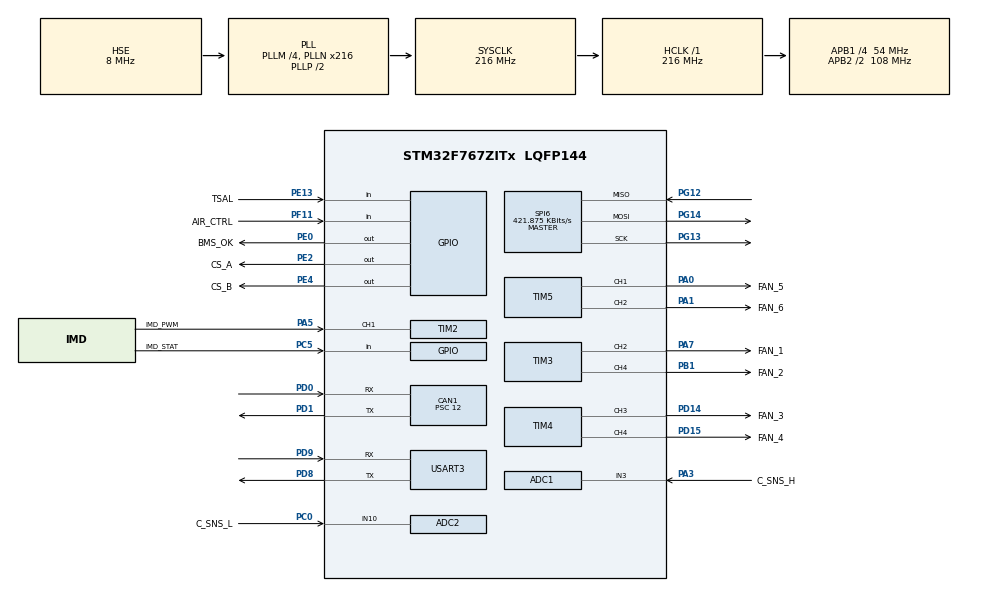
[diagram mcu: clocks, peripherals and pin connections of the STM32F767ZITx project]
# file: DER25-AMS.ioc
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ADC1.Channel-0\#ChannelRegularConversion=ADC_CHANNEL_3
ADC1.ClockPrescaler=ADC_CLOCK_SYNC_PCLK_DIV6
ADC1.NbrOfConversionFlag=1
ADC1.Rank-0\#ChannelRegularConversion=1
ADC1.SamplingTime-0\#ChannelRegularConversion=ADC_SAMPLETIME_3CYCLES
ADC1.master=1
ADC2.Channel-0\#ChannelRegularConversion=ADC_CHANNEL_10
ADC2.ClockPrescaler=ADC_CLOCK_SYNC_PCLK_DIV6
ADC2.NbrOfConversionFlag=1
ADC2.Rank-0\#ChannelRegularConversion=1
ADC2.SamplingTime-0\#ChannelRegularConversion=ADC_SAMPLETIME_3CYCLES
CAN1.ABOM=ENABLE
CAN1.AWUM=ENABLE
CAN1.BS1=CAN_BS1_15TQ
CAN1.BS2=CAN_BS2_2TQ
CAN1.CalculateBaudRate=250000
CAN1.CalculateTimeBit=4000
CAN1.CalculateTimeQuantum=222.22222222222223
CAN1.Prescaler=12
CORTEX_M7.MPU_Control=__NULL
CORTEX_M7.default_mode_Activation=1
FREERTOS.Tasks01=defaultTask,24,128,StartDefaultTask,Default,NULL,Dynamic,NULL,NULL
FREERTOS.configENABLE_FPU=1
FREERTOS.configUSE_NEWLIB_REENTRANT=1
Mcu.Family=STM32F7
Mcu.Name=STM32F767ZITx
Mcu.Package=LQFP144
NVIC.CAN1_RX0_IRQn=true\:5\:0\:false\:false\:true\:true\:true\:true\:true
NVIC.PriorityGroup=NVIC_PRIORITYGROUP_4
NVIC.TIM2_IRQn=true\:5\:0\:false\:false\:true\:true\:true\:true\:true
NVIC.TIM7_IRQn=true\:15\:0\:false\:false\:true\:false\:false\:true\:true
NVIC.TimeBase=TIM7_IRQn
NVIC.TimeBaseIP=TIM7
NVIC.USART3_IRQn=true\:5\:0\:false\:false\:true\:true\:true\:true\:true
PA0/WKUP.GPIO_Label=FAN_5
PA0/WKUP.Signal=S_TIM5_CH1
PA1.GPIO_Label=FAN_6
PA1.Signal=S_TIM5_CH2
PA13.Mode=Serial_Wire
PA13.Signal=SYS_JTMS-SWDIO
PA14.Mode=Serial_Wire
PA14.Signal=SYS_JTCK-SWCLK
PA3.GPIO_Label=C_SNS_H
PA3.Signal=ADCx_IN3
PA5.GPIO_Label=IMD_PWM
PA5.Signal=S_TIM2_CH1_ETR
PA7.GPIO_Label=FAN_1
PA7.Signal=S_TIM3_CH2
PB1.GPIO_Label=FAN_2
PB1.Signal=S_TIM3_CH4
PC0.GPIO_Label=C_SNS_L
PC0.Signal=ADCx_IN10
PC14/OSC32_IN.Mode=LSE-External-Oscillator
PC14/OSC32_IN.Signal=RCC_OSC32_IN
PC15/OSC32_OUT.Mode=LSE-External-Oscillator
PC15/OSC32_OUT.Signal=RCC_OSC32_OUT
PC5.GPIO_Label=IMD_STAT
PC5.Signal=GPIO_Input
PD0.Mode=CAN_Activate
PD0.Signal=CAN1_RX
PD1.Mode=CAN_Activate
PD1.Signal=CAN1_TX
PD14.GPIO_Label=FAN_3
PD14.Signal=S_TIM4_CH3
PD15.GPIO_Label=FAN_4
PD15.Signal=S_TIM4_CH4
PD8.Mode=Asynchronous
PD8.Signal=USART3_TX
PD9.Mode=Asynchronous
PD9.Signal=USART3_RX
PE0.GPIO_Label=BMS_OK
PE0.Signal=GPIO_Output
PE13.GPIO_Label=TSAL
PE13.Signal=GPIO_Input
PE2.GPIO_Label=CS_A
PE2.Signal=GPIO_Output
PE4.GPIO_Label=CS_B
PE4.Signal=GPIO_Output
PF11.GPIO_Label=AIR_CTRL
PF11.Signal=GPIO_Input
PG12.Mode=Full_Duplex_Master
PG12.Signal=SPI6_MISO
PG13.Mode=Full_Duplex_Master
PG13.Signal=SPI6_SCK
PG14.Mode=Full_Duplex_Master
PG14.Signal=SPI6_MOSI
PH0/OSC_IN.Mode=HSE-External-Oscillator
PH0/OSC_IN.Signal=RCC_OSC_IN
PH1/OSC_OUT.Mode=HSE-External-Oscillator
PH1/OSC_OUT.Signal=RCC_OSC_OUT
ProjectManager.HeapSize=0x200
ProjectManager.StackSize=0x400
ProjectManager.TargetToolchain=STM32CubeIDE
RCC.AHBFreq_Value=216000000
RCC.APB1CLKDivider=RCC_HCLK_DIV4
RCC.APB1Freq_Value=54000000
RCC.APB1TimFreq_Value=108000000
RCC.APB2CLKDivider=RCC_HCLK_DIV2
RCC.APB2Freq_Value=108000000
RCC.APB2TimFreq_Value=216000000
RCC.CortexFreq_Value=216000000
RCC.HCLKFreq_Value=216000000
RCC.HSE_VALUE=8000000
RCC.HSI_VALUE=16000000
RCC.PLLM=4
RCC.PLLN=216
RCC.PLLSourceVirtual=RCC_PLLSOURCE_HSE
RCC.SYSCLKFreq_VALUE=216000000
RCC.SYSCLKSource=RCC_SYSCLKSOURCE_PLLCLK
RCC.USBFreq_Value=216000000
RCC.VCOOutputFreq_Value=432000000
SH.ADCx_IN10.0=ADC2_IN10,IN10
SH.ADCx_IN3.0=ADC1_IN3,IN3
SH.S_TIM2_CH1_ETR.0=TIM2_CH1,PWM_Input_1
SH.S_TIM3_CH2.0=TIM3_CH2,PWM Generation2 CH2
SH.S_TIM3_CH4.0=TIM3_CH4,PWM Generation4 CH4
SH.S_TIM4_CH3.0=TIM4_CH3,PWM Generation3 CH3
SH.S_TIM4_CH4.0=TIM4_CH4,PWM Generation4 CH4
SH.S_TIM5_CH1.0=TIM5_CH1,PWM Generation1 CH1
SH.S_TIM5_CH2.0=TIM5_CH2,PWM Generation2 CH2
SPI6.BaudRatePrescaler=SPI_BAUDRATEPRESCALER_256
SPI6.CLKPhase=SPI_PHASE_2EDGE
SPI6.CLKPolarity=SPI_POLARITY_LOW
SPI6.CalculateBaudRate=421.875 KBits/s
SPI6.DataSize=SPI_DATASIZE_8BIT
SPI6.Direction=SPI_DIRECTION_2LINES
SPI6.Mode=SPI_MODE_MASTER
SPI6.VirtualType=VM_MASTER
TIM1.AutoReloadPreload=TIM_AUTORELOAD_PRELOAD_ENABLE
TIM1.Prescaler=215
TIM3.Channel-PWM\ Generation2\ CH2=TIM_CHANNEL_2
TIM3.Channel-PWM\ Generation4\ CH4=TIM_CHANNEL_4
TIM4.Channel-PWM\ Generation3\ CH3=TIM_CHANNEL_3
TIM4.Channel-PWM\ Generation4\ CH4=TIM_CHANNEL_4
TIM5.Channel-PWM\ Generation1\ CH1=TIM_CHANNEL_1
TIM5.Channel-PWM\ Generation2\ CH2=TIM_CHANNEL_2
USART3.VirtualMode-Asynchronous=VM_ASYNC
VP_FREERTOS_VS_CMSIS_V2.Mode=CMSIS_V2
VP_SYS_VS_tim7.Mode=TIM7
VP_TIM1_VS_ClockSourceINT.Mode=Internal
VP_TIM2_VS_ClockSourceINT.Mode=Internal
VP_TIM3_VS_ClockSourceINT.Mode=Internal
VP_TIM4_VS_ClockSourceINT.Mode=Internal
VP_TIM5_VS_ClockSourceINT.Mode=Internal
board=custom

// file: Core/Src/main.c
/* USER CODE BEGIN Header */
/**
  ******************************************************************************
  * @file           : main.c
  * @brief          : Main program body
  ******************************************************************************
  * @attention
  *
  * Copyright (c) 2025 STMicroelectronics.
  * All rights reserved.
  *
  * This software is licensed under terms that can be found in the LICENSE file
  * in the root directory of this software component.
  * If no LICENSE file comes with this software, it is provided AS-IS.
  *
  ******************************************************************************
  */
/* USER CODE END Header */
#include "main.h"
#include "cmsis_os.h"

/* USER CODE BEGIN Includes */
#include "app.h"
/* USER CODE END Includes */

ADC_HandleTypeDef hadc1;
ADC_HandleTypeDef hadc2;

CAN_HandleTypeDef hcan1;

SPI_HandleTypeDef hspi6;

TIM_HandleTypeDef htim1;
TIM_HandleTypeDef htim2;
TIM_HandleTypeDef htim3;
TIM_HandleTypeDef htim4;
TIM_HandleTypeDef htim5;

UART_HandleTypeDef huart3;

/* Definitions for defaultTask */
osThreadId_t defaultTaskHandle;
const osThreadAttr_t defaultTask_attributes = {
  .name = "defaultTask",
  .stack_size = 128 * 4,
  .priority = (osPriority_t) osPriorityNormal,
};

void SystemClock_Config(void);
static void MX_GPIO_Init(void);
static void MX_ADC1_Init(void);
static void MX_ADC2_Init(void);
static void MX_CAN1_Init(void);
static void MX_SPI6_Init(void);
static void MX_TIM2_Init(void);
static void MX_TIM3_Init(void);
static void MX_TIM4_Init(void);
static void MX_TIM5_Init(void);
static void MX_USART3_UART_Init(void);
static void MX_TIM1_Init(void);
void StartDefaultTask(void *argument);

int main(void)
{

  /* MCU Configuration--------------------------------------------------------*/

  /* Reset of all peripherals, Initializes the Flash interface and the Systick. */
  HAL_Init();

  /* Configure the system clock */
  SystemClock_Config();

  /* Initialize all configured peripherals */
  MX_GPIO_Init();
  MX_ADC1_Init();
  MX_ADC2_Init();
  MX_CAN1_Init();
  MX_SPI6_Init();
  MX_TIM2_Init();
  MX_TIM3_Init();
  MX_TIM4_Init();
  MX_TIM5_Init();
  MX_USART3_UART_Init();
  MX_TIM1_Init();

  /* Init scheduler */
  osKernelInitialize();

  /* USER CODE BEGIN RTOS_QUEUES */
  /* add queues, ... */
#if 0
  /* USER CODE END RTOS_QUEUES */

  /* Create the thread(s) */
  /* creation of defaultTask */
  defaultTaskHandle = osThreadNew(StartDefaultTask, NULL, &defaultTask_attributes);

  /* USER CODE BEGIN RTOS_THREADS */
#endif
  /* add threads, ... */
  /* USER CODE END RTOS_THREADS */

  /* USER CODE BEGIN RTOS_EVENTS */
  /* add events, ... */
  app_create();
  /* USER CODE END RTOS_EVENTS */

  /* Start scheduler */
  osKernelStart();

  /* We should never get here as control is now taken by the scheduler */

  /* Infinite loop */
  while (1)
  {

  }
}

void SystemClock_Config(void)
{
  RCC_OscInitTypeDef RCC_OscInitStruct = {0};
  RCC_ClkInitTypeDef RCC_ClkInitStruct = {0};

  /** Configure LSE Drive Capability
  */
  HAL_PWR_EnableBkUpAccess();

  /** Configure the main internal regulator output voltage
  */
  __HAL_RCC_PWR_CLK_ENABLE();
  __HAL_PWR_VOLTAGESCALING_CONFIG(PWR_REGULATOR_VOLTAGE_SCALE1);

  /** Initializes the RCC Oscillators according to the specified parameters
  * in the RCC_OscInitTypeDef structure.
  */
  RCC_OscInitStruct.OscillatorType = RCC_OSCILLATORTYPE_HSE;
  RCC_OscInitStruct.HSEState = RCC_HSE_ON;
  RCC_OscInitStruct.PLL.PLLState = RCC_PLL_ON;
  RCC_OscInitStruct.PLL.PLLSource = RCC_PLLSOURCE_HSE;
  RCC_OscInitStruct.PLL.PLLM = 4;
  RCC_OscInitStruct.PLL.PLLN = 216;
  RCC_OscInitStruct.PLL.PLLP = RCC_PLLP_DIV2;
  RCC_OscInitStruct.PLL.PLLQ = 2;
  RCC_OscInitStruct.PLL.PLLR = 2;
  if (HAL_RCC_OscConfig(&RCC_OscInitStruct) != HAL_OK)
  {
    Error_Handler();
  }

  /** Activate the Over-Drive mode
  */
  if (HAL_PWREx_EnableOverDrive() != HAL_OK)
  {
    Error_Handler();
  }

  /** Initializes the CPU, AHB and APB buses clocks
  */
  RCC_ClkInitStruct.ClockType = RCC_CLOCKTYPE_HCLK|RCC_CLOCKTYPE_SYSCLK
                              |RCC_CLOCKTYPE_PCLK1|RCC_CLOCKTYPE_PCLK2;
  RCC_ClkInitStruct.SYSCLKSource = RCC_SYSCLKSOURCE_PLLCLK;
  RCC_ClkInitStruct.AHBCLKDivider = RCC_SYSCLK_DIV1;
  RCC_ClkInitStruct.APB1CLKDivider = RCC_HCLK_DIV4;
  RCC_ClkInitStruct.APB2CLKDivider = RCC_HCLK_DIV2;

  if (HAL_RCC_ClockConfig(&RCC_ClkInitStruct, FLASH_LATENCY_7) != HAL_OK)
  {
    Error_Handler();
  }
}

static void MX_ADC1_Init(void)
{

  ADC_ChannelConfTypeDef sConfig = {0};

  /** Configure the global features of the ADC (Clock, Resolution, Data Alignment and number of conversion)
  */
  hadc1.Instance = ADC1;
  hadc1.Init.ClockPrescaler = ADC_CLOCK_SYNC_PCLK_DIV6;
  hadc1.Init.Resolution = ADC_RESOLUTION_12B;
  hadc1.Init.ScanConvMode = ADC_SCAN_DISABLE;
  hadc1.Init.ContinuousConvMode = DISABLE;
  hadc1.Init.DiscontinuousConvMode = DISABLE;
  hadc1.Init.ExternalTrigConvEdge = ADC_EXTERNALTRIGCONVEDGE_NONE;
  hadc1.Init.ExternalTrigConv = ADC_SOFTWARE_START;
  hadc1.Init.DataAlign = ADC_DATAALIGN_RIGHT;
  hadc1.Init.NbrOfConversion = 1;
  hadc1.Init.DMAContinuousRequests = DISABLE;
  hadc1.Init.EOCSelection = ADC_EOC_SINGLE_CONV;
  if (HAL_ADC_Init(&hadc1) != HAL_OK)
  {
    Error_Handler();
  }

  /** Configure for the selected ADC regular channel its corresponding rank in the sequencer and its sample time.
  */
  sConfig.Channel = ADC_CHANNEL_3;
  sConfig.Rank = ADC_REGULAR_RANK_1;
  sConfig.SamplingTime = ADC_SAMPLETIME_3CYCLES;
  if (HAL_ADC_ConfigChannel(&hadc1, &sConfig) != HAL_OK)
  {
    Error_Handler();
  }

}

static void MX_ADC2_Init(void)
{

  ADC_ChannelConfTypeDef sConfig = {0};

  /** Configure the global features of the ADC (Clock, Resolution, Data Alignment and number of conversion)
  */
  hadc2.Instance = ADC2;
  hadc2.Init.ClockPrescaler = ADC_CLOCK_SYNC_PCLK_DIV6;
  hadc2.Init.Resolution = ADC_RESOLUTION_12B;
  hadc2.Init.ScanConvMode = ADC_SCAN_DISABLE;
  hadc2.Init.ContinuousConvMode = DISABLE;
  hadc2.Init.DiscontinuousConvMode = DISABLE;
  hadc2.Init.ExternalTrigConvEdge = ADC_EXTERNALTRIGCONVEDGE_NONE;
  hadc2.Init.ExternalTrigConv = ADC_SOFTWARE_START;
  hadc2.Init.DataAlign = ADC_DATAALIGN_RIGHT;
  hadc2.Init.NbrOfConversion = 1;
  hadc2.Init.DMAContinuousRequests = DISABLE;
  hadc2.Init.EOCSelection = ADC_EOC_SINGLE_CONV;
  if (HAL_ADC_Init(&hadc2) != HAL_OK)
  {
    Error_Handler();
  }

  /** Configure for the selected ADC regular channel its corresponding rank in the sequencer and its sample time.
  */
  sConfig.Channel = ADC_CHANNEL_10;
  sConfig.Rank = ADC_REGULAR_RANK_1;
  sConfig.SamplingTime = ADC_SAMPLETIME_3CYCLES;
  if (HAL_ADC_ConfigChannel(&hadc2, &sConfig) != HAL_OK)
  {
    Error_Handler();
  }

}

static void MX_CAN1_Init(void)
{

  hcan1.Instance = CAN1;
  hcan1.Init.Prescaler = 12;
  hcan1.Init.Mode = CAN_MODE_NORMAL;
  hcan1.Init.SyncJumpWidth = CAN_SJW_1TQ;
  hcan1.Init.TimeSeg1 = CAN_BS1_15TQ;
  hcan1.Init.TimeSeg2 = CAN_BS2_2TQ;
  hcan1.Init.TimeTriggeredMode = DISABLE;
  hcan1.Init.AutoBusOff = ENABLE;
  hcan1.Init.AutoWakeUp = ENABLE;
  hcan1.Init.AutoRetransmission = DISABLE;
  hcan1.Init.ReceiveFifoLocked = DISABLE;
  hcan1.Init.TransmitFifoPriority = DISABLE;
  if (HAL_CAN_Init(&hcan1) != HAL_OK)
  {
    Error_Handler();
  }

}

static void MX_SPI6_Init(void)
{

  /* SPI6 parameter configuration*/
  hspi6.Instance = SPI6;
  hspi6.Init.Mode = SPI_MODE_MASTER;
  hspi6.Init.Direction = SPI_DIRECTION_2LINES;
  hspi6.Init.DataSize = SPI_DATASIZE_8BIT;
  hspi6.Init.CLKPolarity = SPI_POLARITY_LOW;
  hspi6.Init.CLKPhase = SPI_PHASE_2EDGE;
  hspi6.Init.NSS = SPI_NSS_SOFT;
  hspi6.Init.BaudRatePrescaler = SPI_BAUDRATEPRESCALER_256;
  hspi6.Init.FirstBit = SPI_FIRSTBIT_MSB;
  hspi6.Init.TIMode = SPI_TIMODE_DISABLE;
  hspi6.Init.CRCCalculation = SPI_CRCCALCULATION_DISABLE;
  hspi6.Init.CRCPolynomial = 7;
  hspi6.Init.CRCLength = SPI_CRC_LENGTH_DATASIZE;
  hspi6.Init.NSSPMode = SPI_NSS_PULSE_DISABLE;
  if (HAL_SPI_Init(&hspi6) != HAL_OK)
  {
    Error_Handler();
  }

}

static void MX_TIM1_Init(void)
{

  TIM_ClockConfigTypeDef sClockSourceConfig = {0};
  TIM_MasterConfigTypeDef sMasterConfig = {0};

  htim1.Instance = TIM1;
  htim1.Init.Prescaler = 215;
  htim1.Init.CounterMode = TIM_COUNTERMODE_UP;
  htim1.Init.Period = 65535;
  htim1.Init.ClockDivision = TIM_CLOCKDIVISION_DIV1;
  htim1.Init.RepetitionCounter = 0;
  htim1.Init.AutoReloadPreload = TIM_AUTORELOAD_PRELOAD_ENABLE;
  if (HAL_TIM_Base_Init(&htim1) != HAL_OK)
  {
    Error_Handler();
  }
  sClockSourceConfig.ClockSource = TIM_CLOCKSOURCE_INTERNAL;
  if (HAL_TIM_ConfigClockSource(&htim1, &sClockSourceConfig) != HAL_OK)
  {
    Error_Handler();
  }
  sMasterConfig.MasterOutputTrigger = TIM_TRGO_RESET;
  sMasterConfig.MasterOutputTrigger2 = TIM_TRGO2_RESET;
  sMasterConfig.MasterSlaveMode = TIM_MASTERSLAVEMODE_DISABLE;
  if (HAL_TIMEx_MasterConfigSynchronization(&htim1, &sMasterConfig) != HAL_OK)
  {
    Error_Handler();
  }

}

static void MX_TIM2_Init(void)
{

  TIM_ClockConfigTypeDef sClockSourceConfig = {0};
  TIM_SlaveConfigTypeDef sSlaveConfig = {0};
  TIM_IC_InitTypeDef sConfigIC = {0};
  TIM_MasterConfigTypeDef sMasterConfig = {0};

  htim2.Instance = TIM2;
  htim2.Init.Prescaler = 0;
  htim2.Init.CounterMode = TIM_COUNTERMODE_UP;
  htim2.Init.Period = 4294967295;
  htim2.Init.ClockDivision = TIM_CLOCKDIVISION_DIV1;
  htim2.Init.AutoReloadPreload = TIM_AUTORELOAD_PRELOAD_DISABLE;
  if (HAL_TIM_Base_Init(&htim2) != HAL_OK)
  {
    Error_Handler();
  }
  sClockSourceConfig.ClockSource = TIM_CLOCKSOURCE_INTERNAL;
  if (HAL_TIM_ConfigClockSource(&htim2, &sClockSourceConfig) != HAL_OK)
  {
    Error_Handler();
  }
  if (HAL_TIM_IC_Init(&htim2) != HAL_OK)
  {
    Error_Handler();
  }
  sSlaveConfig.SlaveMode = TIM_SLAVEMODE_RESET;
  sSlaveConfig.InputTrigger = TIM_TS_TI1FP1;
  sSlaveConfig.TriggerPolarity = TIM_INPUTCHANNELPOLARITY_RISING;
  sSlaveConfig.TriggerPrescaler = TIM_ICPSC_DIV1;
  sSlaveConfig.TriggerFilter = 0;
  if (HAL_TIM_SlaveConfigSynchro(&htim2, &sSlaveConfig) != HAL_OK)
  {
    Error_Handler();
  }
  sConfigIC.ICPolarity = TIM_INPUTCHANNELPOLARITY_RISING;
  sConfigIC.ICSelection = TIM_ICSELECTION_DIRECTTI;
  sConfigIC.ICPrescaler = TIM_ICPSC_DIV1;
  sConfigIC.ICFilter = 0;
  if (HAL_TIM_IC_ConfigChannel(&htim2, &sConfigIC, TIM_CHANNEL_1) != HAL_OK)
  {
    Error_Handler();
  }
  sConfigIC.ICPolarity = TIM_INPUTCHANNELPOLARITY_FALLING;
  sConfigIC.ICSelection = TIM_ICSELECTION_INDIRECTTI;
  if (HAL_TIM_IC_ConfigChannel(&htim2, &sConfigIC, TIM_CHANNEL_2) != HAL_OK)
  {
    Error_Handler();
  }
  sMasterConfig.MasterOutputTrigger = TIM_TRGO_RESET;
  sMasterConfig.MasterSlaveMode = TIM_MASTERSLAVEMODE_DISABLE;
  if (HAL_TIMEx_MasterConfigSynchronization(&htim2, &sMasterConfig) != HAL_OK)
  {
    Error_Handler();
  }

}

static void MX_TIM3_Init(void)
{

  TIM_ClockConfigTypeDef sClockSourceConfig = {0};
  TIM_MasterConfigTypeDef sMasterConfig = {0};
  TIM_OC_InitTypeDef sConfigOC = {0};

  htim3.Instance = TIM3;
  htim3.Init.Prescaler = 0;
  htim3.Init.CounterMode = TIM_COUNTERMODE_UP;
  htim3.Init.Period = 3360;
  htim3.Init.ClockDivision = TIM_CLOCKDIVISION_DIV1;
  htim3.Init.AutoReloadPreload = TIM_AUTORELOAD_PRELOAD_ENABLE;
  if (HAL_TIM_Base_Init(&htim3) != HAL_OK)
  {
    Error_Handler();
  }
  sClockSourceConfig.ClockSource = TIM_CLOCKSOURCE_INTERNAL;
  if (HAL_TIM_ConfigClockSource(&htim3, &sClockSourceConfig) != HAL_OK)
  {
    Error_Handler();
  }
  if (HAL_TIM_PWM_Init(&htim3) != HAL_OK)
  {
    Error_Handler();
  }
  sMasterConfig.MasterOutputTrigger = TIM_TRGO_RESET;
  sMasterConfig.MasterSlaveMode = TIM_MASTERSLAVEMODE_DISABLE;
  if (HAL_TIMEx_MasterConfigSynchronization(&htim3, &sMasterConfig) != HAL_OK)
  {
    Error_Handler();
  }
  sConfigOC.OCMode = TIM_OCMODE_PWM1;
  sConfigOC.Pulse = 0;
  sConfigOC.OCPolarity = TIM_OCPOLARITY_HIGH;
  sConfigOC.OCFastMode = TIM_OCFAST_DISABLE;
  if (HAL_TIM_PWM_ConfigChannel(&htim3, &sConfigOC, TIM_CHANNEL_2) != HAL_OK)
  {
    Error_Handler();
  }
  if (HAL_TIM_PWM_ConfigChannel(&htim3, &sConfigOC, TIM_CHANNEL_4) != HAL_OK)
  {
    Error_Handler();
  }
  HAL_TIM_MspPostInit(&htim3);

}

static void MX_TIM4_Init(void)
{

  TIM_ClockConfigTypeDef sClockSourceConfig = {0};
  TIM_MasterConfigTypeDef sMasterConfig = {0};
  TIM_OC_InitTypeDef sConfigOC = {0};

  htim4.Instance = TIM4;
  htim4.Init.Prescaler = 0;
  htim4.Init.CounterMode = TIM_COUNTERMODE_UP;
  htim4.Init.Period = 3360;
  htim4.Init.ClockDivision = TIM_CLOCKDIVISION_DIV1;
  htim4.Init.AutoReloadPreload = TIM_AUTORELOAD_PRELOAD_ENABLE;
  if (HAL_TIM_Base_Init(&htim4) != HAL_OK)
  {
    Error_Handler();
  }
  sClockSourceConfig.ClockSource = TIM_CLOCKSOURCE_INTERNAL;
  if (HAL_TIM_ConfigClockSource(&htim4, &sClockSourceConfig) != HAL_OK)
  {
    Error_Handler();
  }
  if (HAL_TIM_PWM_Init(&htim4) != HAL_OK)
  {
    Error_Handler();
  }
  sMasterConfig.MasterOutputTrigger = TIM_TRGO_RESET;
  sMasterConfig.MasterSlaveMode = TIM_MASTERSLAVEMODE_DISABLE;
  if (HAL_TIMEx_MasterConfigSynchronization(&htim4, &sMasterConfig) != HAL_OK)
  {
    Error_Handler();
  }
  sConfigOC.OCMode = TIM_OCMODE_PWM1;
  sConfigOC.Pulse = 0;
  sConfigOC.OCPolarity = TIM_OCPOLARITY_HIGH;
  sConfigOC.OCFastMode = TIM_OCFAST_DISABLE;
  if (HAL_TIM_PWM_ConfigChannel(&htim4, &sConfigOC, TIM_CHANNEL_3) != HAL_OK)
  {
    Error_Handler();
  }
  if (HAL_TIM_PWM_ConfigChannel(&htim4, &sConfigOC, TIM_CHANNEL_4) != HAL_OK)
  {
    Error_Handler();
  }
  HAL_TIM_MspPostInit(&htim4);

}

static void MX_TIM5_Init(void)
{

  TIM_ClockConfigTypeDef sClockSourceConfig = {0};
  TIM_MasterConfigTypeDef sMasterConfig = {0};
  TIM_OC_InitTypeDef sConfigOC = {0};

  htim5.Instance = TIM5;
  htim5.Init.Prescaler = 0;
  htim5.Init.CounterMode = TIM_COUNTERMODE_UP;
  htim5.Init.Period = 3360;
  htim5.Init.ClockDivision = TIM_CLOCKDIVISION_DIV1;
  htim5.Init.AutoReloadPreload = TIM_AUTORELOAD_PRELOAD_ENABLE;
  if (HAL_TIM_Base_Init(&htim5) != HAL_OK)
  {
    Error_Handler();
  }
  sClockSourceConfig.ClockSource = TIM_CLOCKSOURCE_INTERNAL;
  if (HAL_TIM_ConfigClockSource(&htim5, &sClockSourceConfig) != HAL_OK)
  {
    Error_Handler();
  }
  if (HAL_TIM_PWM_Init(&htim5) != HAL_OK)
  {
    Error_Handler();
  }
  sMasterConfig.MasterOutputTrigger = TIM_TRGO_RESET;
  sMasterConfig.MasterSlaveMode = TIM_MASTERSLAVEMODE_DISABLE;
  if (HAL_TIMEx_MasterConfigSynchronization(&htim5, &sMasterConfig) != HAL_OK)
  {
    Error_Handler();
  }
  sConfigOC.OCMode = TIM_OCMODE_PWM1;
  sConfigOC.Pulse = 0;
  sConfigOC.OCPolarity = TIM_OCPOLARITY_HIGH;
  sConfigOC.OCFastMode = TIM_OCFAST_DISABLE;
  if (HAL_TIM_PWM_ConfigChannel(&htim5, &sConfigOC, TIM_CHANNEL_1) != HAL_OK)
  {
    Error_Handler();
  }
  if (HAL_TIM_PWM_ConfigChannel(&htim5, &sConfigOC, TIM_CHANNEL_2) != HAL_OK)
  {
    Error_Handler();
  }
  HAL_TIM_MspPostInit(&htim5);

}

static void MX_USART3_UART_Init(void)
{

  huart3.Instance = USART3;
  huart3.Init.BaudRate = 115200;
  huart3.Init.WordLength = UART_WORDLENGTH_8B;
  huart3.Init.StopBits = UART_STOPBITS_1;
  huart3.Init.Parity = UART_PARITY_NONE;
  huart3.Init.Mode = UART_MODE_TX_RX;
  huart3.Init.HwFlowCtl = UART_HWCONTROL_NONE;
  huart3.Init.OverSampling = UART_OVERSAMPLING_16;
  huart3.Init.OneBitSampling = UART_ONE_BIT_SAMPLE_DISABLE;
  huart3.AdvancedInit.AdvFeatureInit = UART_ADVFEATURE_NO_INIT;
  if (HAL_UART_Init(&huart3) != HAL_OK)
  {
    Error_Handler();
  }

}

static void MX_GPIO_Init(void)
{
  GPIO_InitTypeDef GPIO_InitStruct = {0};

  /* GPIO Ports Clock Enable */
  __HAL_RCC_GPIOE_CLK_ENABLE();
  __HAL_RCC_GPIOC_CLK_ENABLE();
  __HAL_RCC_GPIOF_CLK_ENABLE();
  __HAL_RCC_GPIOH_CLK_ENABLE();
  __HAL_RCC_GPIOA_CLK_ENABLE();
  __HAL_RCC_GPIOB_CLK_ENABLE();
  __HAL_RCC_GPIOG_CLK_ENABLE();
  __HAL_RCC_GPIOD_CLK_ENABLE();

  /*Configure GPIO pin Output Level */
  HAL_GPIO_WritePin(GPIOE, CS_A_Pin|CS_B_Pin|BMS_OK_Pin, GPIO_PIN_RESET);

  /*Configure GPIO pins : CS_A_Pin CS_B_Pin BMS_OK_Pin */
  GPIO_InitStruct.Pin = CS_A_Pin|CS_B_Pin|BMS_OK_Pin;
  GPIO_InitStruct.Mode = GPIO_MODE_OUTPUT_PP;
  GPIO_InitStruct.Pull = GPIO_NOPULL;
  GPIO_InitStruct.Speed = GPIO_SPEED_FREQ_LOW;
  HAL_GPIO_Init(GPIOE, &GPIO_InitStruct);

  /*Configure GPIO pins : PE3 PE5 PE6 PE7
                           PE8 PE9 PE10 PE11
                           PE12 PE14 PE15 PE1 */
  GPIO_InitStruct.Pin = GPIO_PIN_3|GPIO_PIN_5|GPIO_PIN_6|GPIO_PIN_7
                          |GPIO_PIN_8|GPIO_PIN_9|GPIO_PIN_10|GPIO_PIN_11
                          |GPIO_PIN_12|GPIO_PIN_14|GPIO_PIN_15|GPIO_PIN_1;
  GPIO_InitStruct.Mode = GPIO_MODE_ANALOG;
  GPIO_InitStruct.Pull = GPIO_NOPULL;
  HAL_GPIO_Init(GPIOE, &GPIO_InitStruct);

  /*Configure GPIO pins : PC13 PC1 PC2 PC3
                           PC4 PC6 PC7 PC8
                           PC9 PC10 PC11 PC12 */
  GPIO_InitStruct.Pin = GPIO_PIN_13|GPIO_PIN_1|GPIO_PIN_2|GPIO_PIN_3
                          |GPIO_PIN_4|GPIO_PIN_6|GPIO_PIN_7|GPIO_PIN_8
                          |GPIO_PIN_9|GPIO_PIN_10|GPIO_PIN_11|GPIO_PIN_12;
  GPIO_InitStruct.Mode = GPIO_MODE_ANALOG;
  GPIO_InitStruct.Pull = GPIO_NOPULL;
  HAL_GPIO_Init(GPIOC, &GPIO_InitStruct);

  /*Configure GPIO pins : PF0 PF1 PF2 PF3
                           PF4 PF5 PF6 PF7
                           PF8 PF9 PF10 PF12
                           PF13 PF14 PF15 */
  GPIO_InitStruct.Pin = GPIO_PIN_0|GPIO_PIN_1|GPIO_PIN_2|GPIO_PIN_3
                          |GPIO_PIN_4|GPIO_PIN_5|GPIO_PIN_6|GPIO_PIN_7
                          |GPIO_PIN_8|GPIO_PIN_9|GPIO_PIN_10|GPIO_PIN_12
                          |GPIO_PIN_13|GPIO_PIN_14|GPIO_PIN_15;
  GPIO_InitStruct.Mode = GPIO_MODE_ANALOG;
  GPIO_InitStruct.Pull = GPIO_NOPULL;
  HAL_GPIO_Init(GPIOF, &GPIO_InitStruct);

  /*Configure GPIO pins : PA2 PA4 PA6 PA8
                           PA9 PA10 PA11 PA12
                           PA15 */
  GPIO_InitStruct.Pin = GPIO_PIN_2|GPIO_PIN_4|GPIO_PIN_6|GPIO_PIN_8
                          |GPIO_PIN_9|GPIO_PIN_10|GPIO_PIN_11|GPIO_PIN_12
                          |GPIO_PIN_15;
  GPIO_InitStruct.Mode = GPIO_MODE_ANALOG;
  GPIO_InitStruct.Pull = GPIO_NOPULL;
  HAL_GPIO_Init(GPIOA, &GPIO_InitStruct);

  /*Configure GPIO pin : IMD_STAT_Pin */
  GPIO_InitStruct.Pin = IMD_STAT_Pin;
  GPIO_InitStruct.Mode = GPIO_MODE_INPUT;
  GPIO_InitStruct.Pull = GPIO_NOPULL;
  HAL_GPIO_Init(IMD_STAT_GPIO_Port, &GPIO_InitStruct);

  /*Configure GPIO pins : PB0 PB2 PB10 PB11
                           PB12 PB13 PB14 PB15
                           PB3 PB4 PB5 PB6
                           PB7 PB8 PB9 */
  GPIO_InitStruct.Pin = GPIO_PIN_0|GPIO_PIN_2|GPIO_PIN_10|GPIO_PIN_11
                          |GPIO_PIN_12|GPIO_PIN_13|GPIO_PIN_14|GPIO_PIN_15
                          |GPIO_PIN_3|GPIO_PIN_4|GPIO_PIN_5|GPIO_PIN_6
                          |GPIO_PIN_7|GPIO_PIN_8|GPIO_PIN_9;
  GPIO_InitStruct.Mode = GPIO_MODE_ANALOG;
  GPIO_InitStruct.Pull = GPIO_NOPULL;
  HAL_GPIO_Init(GPIOB, &GPIO_InitStruct);

  /*Configure GPIO pin : AIR_CTRL_Pin */
  GPIO_InitStruct.Pin = AIR_CTRL_Pin;
  GPIO_InitStruct.Mode = GPIO_MODE_INPUT;
  GPIO_InitStruct.Pull = GPIO_NOPULL;
  HAL_GPIO_Init(AIR_CTRL_GPIO_Port, &GPIO_InitStruct);

  /*Configure GPIO pins : PG0 PG1 PG2 PG3
                           PG4 PG5 PG6 PG7
                           PG8 PG9 PG10 PG11
                           PG15 */
  GPIO_InitStruct.Pin = GPIO_PIN_0|GPIO_PIN_1|GPIO_PIN_2|GPIO_PIN_3
                          |GPIO_PIN_4|GPIO_PIN_5|GPIO_PIN_6|GPIO_PIN_7
                          |GPIO_PIN_8|GPIO_PIN_9|GPIO_PIN_10|GPIO_PIN_11
                          |GPIO_PIN_15;
  GPIO_InitStruct.Mode = GPIO_MODE_ANALOG;
  GPIO_InitStruct.Pull = GPIO_NOPULL;
  HAL_GPIO_Init(GPIOG, &GPIO_InitStruct);

  /*Configure GPIO pin : TSAL_Pin */
  GPIO_InitStruct.Pin = TSAL_Pin;
  GPIO_InitStruct.Mode = GPIO_MODE_INPUT;
  GPIO_InitStruct.Pull = GPIO_NOPULL;
  HAL_GPIO_Init(TSAL_GPIO_Port, &GPIO_InitStruct);

  /*Configure GPIO pins : PD10 PD11 PD12 PD13
                           PD2 PD3 PD4 PD5
                           PD6 PD7 */
  GPIO_InitStruct.Pin = GPIO_PIN_10|GPIO_PIN_11|GPIO_PIN_12|GPIO_PIN_13
                          |GPIO_PIN_2|GPIO_PIN_3|GPIO_PIN_4|GPIO_PIN_5
                          |GPIO_PIN_6|GPIO_PIN_7;
  GPIO_InitStruct.Mode = GPIO_MODE_ANALOG;
  GPIO_InitStruct.Pull = GPIO_NOPULL;
  HAL_GPIO_Init(GPIOD, &GPIO_InitStruct);

}

void StartDefaultTask(void *argument)
{
  for(;;)
  {
    osDelay(1);
  }
}

void HAL_TIM_PeriodElapsedCallback(TIM_HandleTypeDef *htim)
{
  if (htim->Instance == TIM7) {
    HAL_IncTick();
  }
}

void Error_Handler(void)
{
  __disable_irq();
  while (1)
  {
  }
}
